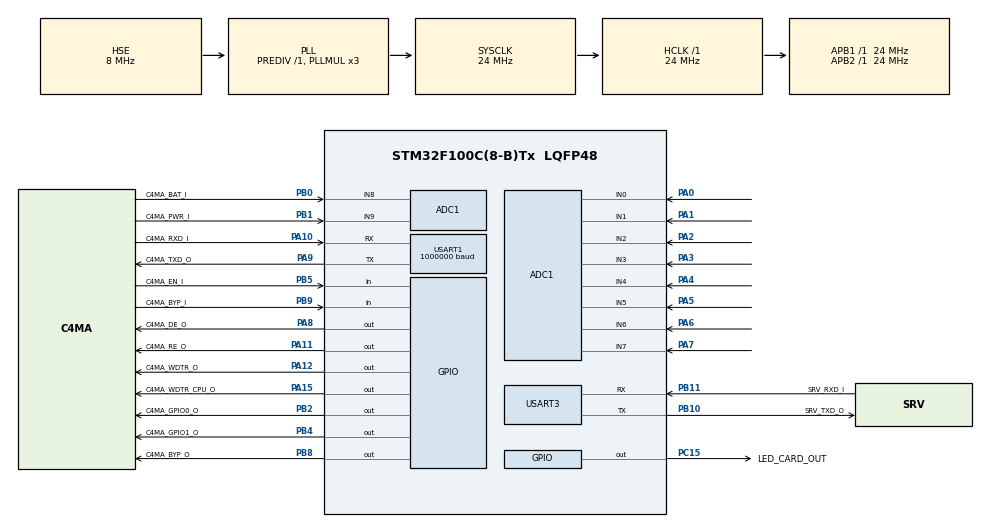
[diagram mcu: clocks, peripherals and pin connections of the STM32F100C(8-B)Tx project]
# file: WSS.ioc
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ADC1.Channel-0\#ChannelRegularConversion=ADC_CHANNEL_7
ADC1.Channel-1\#ChannelRegularConversion=ADC_CHANNEL_6
ADC1.Channel-11\#ChannelRegularConversion=ADC_CHANNEL_9
ADC1.Channel-12\#ChannelRegularConversion=ADC_CHANNEL_8
ADC1.Channel-2\#ChannelRegularConversion=ADC_CHANNEL_5
ADC1.Channel-3\#ChannelRegularConversion=ADC_CHANNEL_4
ADC1.Channel-4\#ChannelRegularConversion=ADC_CHANNEL_3
ADC1.Channel-5\#ChannelRegularConversion=ADC_CHANNEL_2
ADC1.Channel-6\#ChannelRegularConversion=ADC_CHANNEL_1
ADC1.Channel-7\#ChannelRegularConversion=ADC_CHANNEL_0
ADC1.Channel-8\#ChannelRegularConversion=ADC_CHANNEL_VREFINT
ADC1.Channel-9\#ChannelRegularConversion=ADC_CHANNEL_TEMPSENSOR
ADC1.ContinuousConvMode=ENABLE
ADC1.EnableInjectedConversion=DISABLE
ADC1.InjNumberOfConversion=0
ADC1.NbrOfConversion=12
ADC1.NbrOfConversionFlag=1
ADC1.Rank-0\#ChannelRegularConversion=1
ADC1.Rank-1\#ChannelRegularConversion=2
ADC1.Rank-11\#ChannelRegularConversion=11
ADC1.Rank-12\#ChannelRegularConversion=12
ADC1.Rank-2\#ChannelRegularConversion=3
ADC1.Rank-3\#ChannelRegularConversion=4
ADC1.Rank-4\#ChannelRegularConversion=5
ADC1.Rank-5\#ChannelRegularConversion=6
ADC1.Rank-6\#ChannelRegularConversion=7
ADC1.Rank-7\#ChannelRegularConversion=8
ADC1.Rank-8\#ChannelRegularConversion=9
ADC1.Rank-9\#ChannelRegularConversion=10
ADC1.SamplingTime-0\#ChannelRegularConversion=ADC_SAMPLETIME_71CYCLES_5
ADC1.SamplingTime-1\#ChannelRegularConversion=ADC_SAMPLETIME_71CYCLES_5
ADC1.SamplingTime-11\#ChannelRegularConversion=ADC_SAMPLETIME_71CYCLES_5
ADC1.SamplingTime-12\#ChannelRegularConversion=ADC_SAMPLETIME_71CYCLES_5
ADC1.SamplingTime-2\#ChannelRegularConversion=ADC_SAMPLETIME_71CYCLES_5
ADC1.SamplingTime-3\#ChannelRegularConversion=ADC_SAMPLETIME_71CYCLES_5
ADC1.SamplingTime-4\#ChannelRegularConversion=ADC_SAMPLETIME_71CYCLES_5
ADC1.SamplingTime-5\#ChannelRegularConversion=ADC_SAMPLETIME_71CYCLES_5
ADC1.SamplingTime-6\#ChannelRegularConversion=ADC_SAMPLETIME_71CYCLES_5
ADC1.SamplingTime-7\#ChannelRegularConversion=ADC_SAMPLETIME_71CYCLES_5
ADC1.SamplingTime-8\#ChannelRegularConversion=ADC_SAMPLETIME_71CYCLES_5
ADC1.SamplingTime-9\#ChannelRegularConversion=ADC_SAMPLETIME_71CYCLES_5
ADC1.master=1
Dma.ADC1.0.Direction=DMA_PERIPH_TO_MEMORY
Dma.ADC1.0.Instance=DMA1_Channel1
Dma.ADC1.0.MemDataAlignment=DMA_MDATAALIGN_HALFWORD
Dma.ADC1.0.MemInc=DMA_MINC_ENABLE
Dma.ADC1.0.Mode=DMA_CIRCULAR
Dma.ADC1.0.PeriphDataAlignment=DMA_PDATAALIGN_HALFWORD
Dma.ADC1.0.PeriphInc=DMA_PINC_DISABLE
Dma.ADC1.0.Priority=DMA_PRIORITY_HIGH
Dma.Request0=ADC1
Dma.Request1=USART1_RX
Dma.USART1_RX.1.Direction=DMA_PERIPH_TO_MEMORY
Dma.USART1_RX.1.Instance=DMA1_Channel5
Dma.USART1_RX.1.MemDataAlignment=DMA_MDATAALIGN_BYTE
Dma.USART1_RX.1.MemInc=DMA_MINC_ENABLE
Dma.USART1_RX.1.Mode=DMA_CIRCULAR
Dma.USART1_RX.1.PeriphDataAlignment=DMA_PDATAALIGN_BYTE
Dma.USART1_RX.1.PeriphInc=DMA_PINC_DISABLE
Dma.USART1_RX.1.Priority=DMA_PRIORITY_LOW
Mcu.Family=STM32F1
Mcu.Name=STM32F100C(8-B)Tx
Mcu.Package=LQFP48
NVIC.ADC1_IRQn=true\:0\:0\:false\:false\:true\:true\:true\:true
NVIC.DMA1_Channel1_IRQn=true\:0\:0\:false\:false\:true\:false\:true\:true
NVIC.DMA1_Channel5_IRQn=true\:0\:0\:false\:false\:true\:false\:true\:true
NVIC.PriorityGroup=NVIC_PRIORITYGROUP_4
NVIC.TIM1_UP_TIM16_IRQn=true\:15\:0\:false\:false\:true\:false\:true\:true
NVIC.TimeBase=TIM1_UP_TIM16_IRQn
NVIC.TimeBaseIP=TIM1
PA0-WKUP.Signal=ADCx_IN0
PA1.Signal=ADCx_IN1
PA10.GPIO_Label=C4MA_RXD_I
PA10.GPIO_PuPd=GPIO_PULLUP
PA10.Mode=Asynchronous
PA10.Signal=USART1_RX
PA11.GPIO_Label=C4MA_RE_O
PA11.Signal=GPIO_Output
PA12.GPIO_Label=C4MA_WDTR_O
PA12.Signal=GPIO_Output
PA15.GPIO_Label=C4MA_WDTR_CPU_O
PA15.Signal=GPIO_Output
PA2.Signal=ADCx_IN2
PA3.Signal=ADCx_IN3
PA4.Signal=ADCx_IN4
PA5.Signal=ADCx_IN5
PA6.Signal=ADCx_IN6
PA7.Signal=ADCx_IN7
PA8.GPIO_Label=C4MA_DE_O
PA8.Signal=GPIO_Output
PA9.GPIO_Label=C4MA_TXD_O
PA9.Mode=Asynchronous
PA9.Signal=USART1_TX
PB0.GPIO_Label=C4MA_BAT_I
PB0.Signal=ADCx_IN8
PB1.GPIO_Label=C4MA_PWR_I
PB1.Signal=ADCx_IN9
PB10.GPIO_Label=SRV_TXD_O
PB10.Mode=Asynchronous
PB10.Signal=USART3_TX
PB11.GPIO_Label=SRV_RXD_I
PB11.Mode=Asynchronous
PB11.Signal=USART3_RX
PB2.GPIO_Label=C4MA_GPIO0_O
PB2.GPIO_ModeDefaultOutputPP=GPIO_MODE_OUTPUT_OD
PB2.GPIO_Speed=GPIO_SPEED_FREQ_LOW
PB2.Signal=GPIO_Output
PB4.GPIO_Label=C4MA_GPIO1_O
PB4.GPIO_ModeDefaultOutputPP=GPIO_MODE_OUTPUT_OD
PB4.GPIO_Speed=GPIO_SPEED_FREQ_LOW
PB4.Signal=GPIO_Output
PB5.GPIO_Label=C4MA_EN_I
PB5.Signal=GPIO_Input
PB8.GPIO_Label=C4MA_BYP_O
PB8.GPIO_Speed=GPIO_SPEED_FREQ_HIGH
PB8.Signal=GPIO_Output
PB9.GPIO_Label=C4MA_BYP_I
PB9.Signal=GPIO_Input
PC15-OSC32_OUT.GPIO_Label=LED_CARD_OUT
PC15-OSC32_OUT.Signal=GPIO_Output
PD0-OSC_IN.Mode=HSE-External-Oscillator
PD0-OSC_IN.Signal=RCC_OSC_IN
PD1-OSC_OUT.Mode=HSE-External-Oscillator
PD1-OSC_OUT.Signal=RCC_OSC_OUT
ProjectManager.HeapSize=0x200
ProjectManager.StackSize=0x400
ProjectManager.TargetToolchain=STM32CubeIDE
RCC.AHBFreq_Value=24000000
RCC.APB1Freq_Value=24000000
RCC.APB1TimFreq_Value=24000000
RCC.APB2Freq_Value=24000000
RCC.APB2TimFreq_Value=24000000
RCC.HCLKFreq_Value=24000000
RCC.PLLMUL=RCC_PLL_MUL3
RCC.PLLSource=RCC_PLLSOURCE_HSE
RCC.SYSCLKFreq_VALUE=24000000
RCC.SYSCLKSource=RCC_SYSCLKSOURCE_PLLCLK
SH.ADCx_IN0.0=ADC1_IN0,IN0
SH.ADCx_IN1.0=ADC1_IN1,IN1
SH.ADCx_IN2.0=ADC1_IN2,IN2
SH.ADCx_IN3.0=ADC1_IN3,IN3
SH.ADCx_IN4.0=ADC1_IN4,IN4
SH.ADCx_IN5.0=ADC1_IN5,IN5
SH.ADCx_IN6.0=ADC1_IN6,IN6
SH.ADCx_IN7.0=ADC1_IN7,IN7
SH.ADCx_IN8.0=ADC1_IN8,IN8
SH.ADCx_IN9.0=ADC1_IN9,IN9
USART1.BaudRate=1000000
USART1.OverSampling=UART_OVERSAMPLING_16
USART1.StopBits=STOPBITS_2
USART1.VirtualMode=VM_ASYNC
USART3.VirtualMode=VM_ASYNC
VP_ADC1_TempSens_Input.Mode=IN-TempSens
VP_ADC1_Vref_Input.Mode=IN-Vrefint
VP_CRC_VS_CRC.Mode=CRC_Activate
VP_SYS_VS_ND.Mode=No_Debug
VP_SYS_VS_tim1.Mode=TIM1
board=custom

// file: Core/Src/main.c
/* USER CODE BEGIN Header */
/**
  ******************************************************************************
  * @file           : main.c
  * @brief          : Main program body
  ******************************************************************************
  * @attention
  *
  * Copyright (c) 2022 STMicroelectronics.
  * All rights reserved.
  *
  * This software is licensed under terms that can be found in the LICENSE file
  * in the root directory of this software component.
  * If no LICENSE file comes with this software, it is provided AS-IS.
  *
  ******************************************************************************
  */
/* USER CODE END Header */
#include "main.h"
#include "adc.h"
#include "crc.h"
#include "dma.h"
#include "usart.h"
#include "gpio.h"

void SystemClock_Config(void);

int main(void)
{

  /* MCU Configuration--------------------------------------------------------*/

  /* Reset of all peripherals, Initializes the Flash interface and the Systick. */
  HAL_Init();

  /* Configure the system clock */
  SystemClock_Config();

  /* Initialize all configured peripherals */
  MX_GPIO_Init();
  MX_DMA_Init();
  MX_ADC1_Init();
  MX_CRC_Init();
  MX_USART1_UART_Init();
  MX_USART3_UART_Init();

  /* Infinite loop */
  while (1)
  {

    /* USER CODE BEGIN 3 */
	  HAL_GPIO_TogglePin (LED_CARD_OUT_GPIO_Port, LED_CARD_OUT_Pin);
	  HAL_Delay (1000);
  }
  /* USER CODE END 3 */
}

void SystemClock_Config(void)
{
  RCC_OscInitTypeDef RCC_OscInitStruct = {0};
  RCC_ClkInitTypeDef RCC_ClkInitStruct = {0};
  RCC_PeriphCLKInitTypeDef PeriphClkInit = {0};

  /** Initializes the RCC Oscillators according to the specified parameters
  * in the RCC_OscInitTypeDef structure.
  */
  RCC_OscInitStruct.OscillatorType = RCC_OSCILLATORTYPE_HSE;
  RCC_OscInitStruct.HSEState = RCC_HSE_ON;
  RCC_OscInitStruct.HSEPredivValue = RCC_HSE_PREDIV_DIV1;
  RCC_OscInitStruct.PLL.PLLState = RCC_PLL_ON;
  RCC_OscInitStruct.PLL.PLLSource = RCC_PLLSOURCE_HSE;
  RCC_OscInitStruct.PLL.PLLMUL = RCC_PLL_MUL3;
  if (HAL_RCC_OscConfig(&RCC_OscInitStruct) != HAL_OK)
  {
    Error_Handler();
  }

  /** Initializes the CPU, AHB and APB buses clocks
  */
  RCC_ClkInitStruct.ClockType = RCC_CLOCKTYPE_HCLK|RCC_CLOCKTYPE_SYSCLK
                              |RCC_CLOCKTYPE_PCLK1|RCC_CLOCKTYPE_PCLK2;
  RCC_ClkInitStruct.SYSCLKSource = RCC_SYSCLKSOURCE_PLLCLK;
  RCC_ClkInitStruct.AHBCLKDivider = RCC_SYSCLK_DIV1;
  RCC_ClkInitStruct.APB1CLKDivider = RCC_HCLK_DIV1;
  RCC_ClkInitStruct.APB2CLKDivider = RCC_HCLK_DIV1;

  if (HAL_RCC_ClockConfig(&RCC_ClkInitStruct, FLASH_LATENCY_0) != HAL_OK)
  {
    Error_Handler();
  }
  PeriphClkInit.PeriphClockSelection = RCC_PERIPHCLK_ADC;
  PeriphClkInit.AdcClockSelection = RCC_ADCPCLK2_DIV2;
  if (HAL_RCCEx_PeriphCLKConfig(&PeriphClkInit) != HAL_OK)
  {
    Error_Handler();
  }
}

void HAL_TIM_PeriodElapsedCallback(TIM_HandleTypeDef *htim)
{
  if (htim->Instance == TIM1) {
    HAL_IncTick();
  }
}

void Error_Handler(void)
{
  __disable_irq();
  while (1)
  {
  }
}
